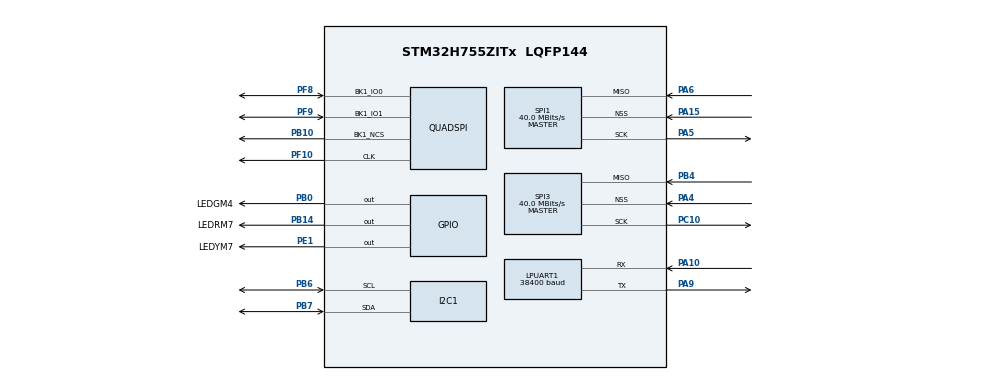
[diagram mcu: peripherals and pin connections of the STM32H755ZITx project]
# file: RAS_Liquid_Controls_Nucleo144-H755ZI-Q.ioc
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CORTEX_M7.default_mode_Activation=1
CortexM4.IPs=CORTEX_M4\:I,FATFS_M4\:I,FREERTOS_M4\:I,IWDG2\:I,OPENAMP_M4\:I,PDM2PCM_M4\:I,PWR,RCC,RESMGR_UTILITY,SYS_M4\:I,USB_DEVICE_M4\:I,USB_HOST_M4\:I,VREFBUF,WWDG2\:I,GPIO,DMA,BDMA,MDMA,NVIC2\:I,TIM7\:I,QUADSPI\:I
CortexM4.Pins=PB0
CortexM7.IPs=CORTEX_M7\:I,FATFS_M7\:I,FREERTOS_M7\:I,IWDG1\:I,OPENAMP_M7\:I,PDM2PCM_M7\:I,PWR\:I,RCC\:I,RESMGR_UTILITY\:I,SYS\:I,USB_DEVICE_M7\:I,USB_HOST_M7\:I,VREFBUF\:I,WWDG1\:I,GPIO\:I,DMA\:I,BDMA\:I,MDMA\:I,NVIC1\:I,TIM6\:I,SPI1\:I,SPI3\:I,I2C1\:I,LPUART1\:I
CortexM7.Pins=PB14,PE1
FREERTOS_M4.Tasks01=defaultTask,24,128,StartDefaultTask,Default,NULL,Dynamic,NULL,NULL
FREERTOS_M4.configUSE_NEWLIB_REENTRANT=1
FREERTOS_M7.Tasks01=defaultTask,24,128,StartDefaultTask,Default,NULL,Dynamic,NULL,NULL
FREERTOS_M7.configUSE_NEWLIB_REENTRANT=1
I2C1.Timing=0x00707CBB
LPUART1.BaudRate=38400
Mcu.Family=STM32H7
Mcu.Name=STM32H755ZITx
Mcu.Package=LQFP144
NVIC1.PriorityGroup=NVIC_PRIORITYGROUP_4
NVIC1.TIM6_DAC_IRQn=true\:15\:0\:false\:false\:true\:false\:false\:true\:true
NVIC1.TimeBase=TIM6_DAC_IRQn
NVIC1.TimeBaseIP=TIM6
NVIC2.PriorityGroup=NVIC_PRIORITYGROUP_4
NVIC2.TIM7_IRQn=true\:15\:0\:false\:false\:true\:false\:false\:true\:true
NVIC2.TimeBase=TIM7_IRQn
NVIC2.TimeBaseIP=TIM7
PA10.Mode=Asynchronous
PA10.PinAttribute=CortexM7
PA10.Signal=LPUART1_RX
PA15\ (JTDI).Mode=NSS_Signal_Hard_Input
PA15\ (JTDI).PinAttribute=CortexM7
PA15\ (JTDI).Signal=SPI1_NSS
PA4.Mode=NSS_Signal_Hard_Input
PA4.PinAttribute=CortexM7
PA4.Signal=SPI3_NSS
PA5.Mode=RX_Only_Simplex_Unidirect_Master
PA5.PinAttribute=CortexM7
PA5.Signal=SPI1_SCK
PA6.Mode=RX_Only_Simplex_Unidirect_Master
PA6.PinAttribute=CortexM7
PA6.Signal=SPI1_MISO
PA9.Mode=Asynchronous
PA9.PinAttribute=CortexM7
PA9.Signal=LPUART1_TX
PB0.GPIO_Label=LEDGM4
PB0.PinAttribute=CortexM4
PB0.Signal=GPIO_Output
PB10.Mode=Single Bank 1 2IOs
PB10.PinAttribute=CortexM4
PB10.Signal=QUADSPI_BK1_NCS
PB14.GPIO_Label=LEDRM7
PB14.PinAttribute=CortexM7
PB14.Signal=GPIO_Output
PB4\ (NJTRST).Mode=RX_Only_Simplex_Unidirect_Master
PB4\ (NJTRST).PinAttribute=CortexM7
PB4\ (NJTRST).Signal=SPI3_MISO
PB6.Mode=I2C
PB6.PinAttribute=CortexM7
PB6.Signal=I2C1_SCL
PB7.Mode=I2C
PB7.PinAttribute=CortexM7
PB7.Signal=I2C1_SDA
PC10.Mode=RX_Only_Simplex_Unidirect_Master
PC10.PinAttribute=CortexM7
PC10.Signal=SPI3_SCK
PE1.GPIO_Label=LEDYM7
PE1.PinAttribute=CortexM7
PE1.Signal=GPIO_Output
PF10.Mode=Single Bank 1 2IOs
PF10.PinAttribute=CortexM4
PF10.Signal=QUADSPI_CLK
PF8.Mode=Single Bank 1 2IOs
PF8.PinAttribute=CortexM4
PF8.Signal=QUADSPI_BK1_IO0
PF9.Mode=Single Bank 1 2IOs
PF9.PinAttribute=CortexM4
PF9.Signal=QUADSPI_BK1_IO1
ProjectManager.HeapSize=M4-0x200,M7-0x200
ProjectManager.StackSize=M4-0x400,M7-0x400
ProjectManager.TargetToolchain=STM32CubeIDE
RCC.ADCFreq_Value=129000000
RCC.APB1Freq_Value=32000000
RCC.APB2Freq_Value=64000000
RCC.APB3Freq_Value=32000000
RCC.APB4Freq_Value=64000000
RCC.CortexFreq_Value=64000000
RCC.D1PPRE=RCC_APB3_DIV2
RCC.D2PPRE1=RCC_APB1_DIV2
RCC.DIVM1=4
RCC.DIVN1=10
RCC.HCLKFreq_Value=64000000
RCC.PLLFRACN=0
RCC.SYSCLKFreq_VALUE=64000000
RCC.USBFreq_Value=80000000
SPI1.CalculateBaudRate=40.0 MBits/s
SPI1.Direction=SPI_DIRECTION_2LINES_RXONLY
SPI1.Mode=SPI_MODE_MASTER
SPI1.VirtualNSS=VM_NSSHARD
SPI1.VirtualType=VM_MASTER
SPI3.CalculateBaudRate=40.0 MBits/s
SPI3.Direction=SPI_DIRECTION_2LINES_RXONLY
SPI3.Mode=SPI_MODE_MASTER
SPI3.VirtualNSS=VM_NSSHARD
SPI3.VirtualType=VM_MASTER
SYS.userName=SYS_M7
VP_FREERTOS_M4_VS_CMSIS_V2.Mode=CMSIS_V2
VP_FREERTOS_M7_VS_CMSIS_V2.Mode=CMSIS_V2
VP_SYS_M4_VS_tim7.Mode=TIM7
VP_SYS_VS_tim6.Mode=TIM6
board=custom

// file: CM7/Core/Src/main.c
/* USER CODE BEGIN Header */
/**
  ******************************************************************************
  * @file           : main.c
  * @brief          : Main program body
  ******************************************************************************
  * @attention
  *
  * Copyright (c) 2026 STMicroelectronics.
  * All rights reserved.
  *
  * This software is licensed under terms that can be found in the LICENSE file
  * in the root directory of this software component.
  * If no LICENSE file comes with this software, it is provided AS-IS.
  *
  ******************************************************************************
  */
/* USER CODE END Header */
#include "main.h"
#include "FreeRTOS.h"
#include "cmsis_os2.h"

/* USER CODE BEGIN PD */

/* DUAL_CORE_BOOT_SYNC_SEQUENCE: Define for dual core boot synchronization    */
/*                             demonstration code based on hardware semaphore */
/* This define is present in both CM7/CM4 projects                            */
/* To comment when developping/debugging on a single core                     */
#define DUAL_CORE_BOOT_SYNC_SEQUENCE

#if defined(DUAL_CORE_BOOT_SYNC_SEQUENCE)
#ifndef HSEM_ID_0
#define HSEM_ID_0 (0U) /* HW semaphore 0*/
#endif
#endif /* DUAL_CORE_BOOT_SYNC_SEQUENCE */

/* USER CODE END PD */

I2C_HandleTypeDef hi2c1;

UART_HandleTypeDef hlpuart1;

SPI_HandleTypeDef hspi1;
SPI_HandleTypeDef hspi3;

/* Definitions for defaultTask */
osThreadId_t defaultTaskHandle;
const osThreadAttr_t defaultTask_attributes = {
  .name = "defaultTask",
  .stack_size = 128 * 4,
  .priority = (osPriority_t) osPriorityNormal,
};

void SystemClock_Config(void);
static void MPU_Config(void);
static void MX_GPIO_Init(void);
static void MX_I2C1_Init(void);
static void MX_LPUART1_UART_Init(void);
static void MX_SPI1_Init(void);
static void MX_SPI3_Init(void);
void StartDefaultTask(void *argument);

int main(void)
{

/* USER CODE BEGIN Boot_Mode_Sequence_0 */
#if defined(DUAL_CORE_BOOT_SYNC_SEQUENCE)
  int32_t timeout;
#endif /* DUAL_CORE_BOOT_SYNC_SEQUENCE */
/* USER CODE END Boot_Mode_Sequence_0 */

  /* MPU Configuration--------------------------------------------------------*/
  MPU_Config();

/* USER CODE BEGIN Boot_Mode_Sequence_1 */
#if defined(DUAL_CORE_BOOT_SYNC_SEQUENCE)
  /* Wait until CPU2 boots and enters in stop mode or timeout*/
  timeout = 0xFFFF;
  while((__HAL_RCC_GET_FLAG(RCC_FLAG_D2CKRDY) != RESET) && (timeout-- > 0));
  if ( timeout < 0 )
  {
	  Error_Handler();
  }
#endif /* DUAL_CORE_BOOT_SYNC_SEQUENCE */
/* USER CODE END Boot_Mode_Sequence_1 */
  /* MCU Configuration--------------------------------------------------------*/

  /* Reset of all peripherals, Initializes the Flash interface and the Systick. */
  HAL_Init();

  /* Configure the system clock */
  SystemClock_Config();
/* USER CODE BEGIN Boot_Mode_Sequence_2 */

#if defined(DUAL_CORE_BOOT_SYNC_SEQUENCE)
/* When system initialization is finished, Cortex-M7 will release Cortex-M4 by means of
HSEM notification */
/*HW semaphore Clock enable*/
__HAL_RCC_HSEM_CLK_ENABLE();
/*Take HSEM */
HAL_HSEM_FastTake(HSEM_ID_0);
/*Release HSEM in order to notify the CPU2(CM4)*/
HAL_HSEM_Release(HSEM_ID_0,0);
/* wait until CPU2 wakes up from stop mode */
timeout = 0xFFFF;
while((__HAL_RCC_GET_FLAG(RCC_FLAG_D2CKRDY) == RESET) && (timeout-- > 0));
if ( timeout < 0 )
{
	Error_Handler();
}
#endif /* DUAL_CORE_BOOT_SYNC_SEQUENCE */
/* USER CODE END Boot_Mode_Sequence_2 */

  /* Initialize all configured peripherals */
  MX_GPIO_Init();
  MX_I2C1_Init();
  MX_LPUART1_UART_Init();
  MX_SPI1_Init();
  MX_SPI3_Init();
  /* USER CODE BEGIN 2 */
  //LED DEBUG
  //HAL_GPIO_WritePin(LEDGM7_GPIO_Port, LEDGM7_Pin, GPIO_PIN_SET);   /* green solid */
  /* USER CODE END 2 */

  /* Init scheduler */
  osKernelInitialize();

  /* Create the thread(s) */
  /* creation of defaultTask */
  defaultTaskHandle = osThreadNew(StartDefaultTask, NULL, &defaultTask_attributes);

  /* Start scheduler */
  osKernelStart();

  /* We should never get here as control is now taken by the scheduler */

  /* Infinite loop */
  while (1)
  {

  }
}

void SystemClock_Config(void)
{
  RCC_OscInitTypeDef RCC_OscInitStruct = {0};
  RCC_ClkInitTypeDef RCC_ClkInitStruct = {0};

  /** Supply configuration update enable
  */
  HAL_PWREx_ConfigSupply(PWR_DIRECT_SMPS_SUPPLY);

  /** Configure the main internal regulator output voltage
  */
  __HAL_PWR_VOLTAGESCALING_CONFIG(PWR_REGULATOR_VOLTAGE_SCALE3);

  while(!__HAL_PWR_GET_FLAG(PWR_FLAG_VOSRDY)) {}

  /** Initializes the RCC Oscillators according to the specified parameters
  * in the RCC_OscInitTypeDef structure.
  */
  RCC_OscInitStruct.OscillatorType = RCC_OSCILLATORTYPE_HSI;
  RCC_OscInitStruct.HSIState = RCC_HSI_DIV1;
  RCC_OscInitStruct.HSICalibrationValue = RCC_HSICALIBRATION_DEFAULT;
  RCC_OscInitStruct.PLL.PLLState = RCC_PLL_ON;
  RCC_OscInitStruct.PLL.PLLSource = RCC_PLLSOURCE_HSI;
  RCC_OscInitStruct.PLL.PLLM = 4;
  RCC_OscInitStruct.PLL.PLLN = 10;
  RCC_OscInitStruct.PLL.PLLP = 2;
  RCC_OscInitStruct.PLL.PLLQ = 2;
  RCC_OscInitStruct.PLL.PLLR = 2;
  RCC_OscInitStruct.PLL.PLLRGE = RCC_PLL1VCIRANGE_3;
  RCC_OscInitStruct.PLL.PLLVCOSEL = RCC_PLL1VCOMEDIUM;
  RCC_OscInitStruct.PLL.PLLFRACN = 0;
  if (HAL_RCC_OscConfig(&RCC_OscInitStruct) != HAL_OK)
  {
    Error_Handler();
  }

  /** Initializes the CPU, AHB and APB buses clocks
  */
  RCC_ClkInitStruct.ClockType = RCC_CLOCKTYPE_HCLK|RCC_CLOCKTYPE_SYSCLK
                              |RCC_CLOCKTYPE_PCLK1|RCC_CLOCKTYPE_PCLK2
                              |RCC_CLOCKTYPE_D3PCLK1|RCC_CLOCKTYPE_D1PCLK1;
  RCC_ClkInitStruct.SYSCLKSource = RCC_SYSCLKSOURCE_HSI;
  RCC_ClkInitStruct.SYSCLKDivider = RCC_SYSCLK_DIV1;
  RCC_ClkInitStruct.AHBCLKDivider = RCC_HCLK_DIV1;
  RCC_ClkInitStruct.APB3CLKDivider = RCC_APB3_DIV2;
  RCC_ClkInitStruct.APB1CLKDivider = RCC_APB1_DIV2;
  RCC_ClkInitStruct.APB2CLKDivider = RCC_APB2_DIV1;
  RCC_ClkInitStruct.APB4CLKDivider = RCC_APB4_DIV1;

  if (HAL_RCC_ClockConfig(&RCC_ClkInitStruct, FLASH_LATENCY_1) != HAL_OK)
  {
    Error_Handler();
  }
}

static void MX_I2C1_Init(void)
{

  hi2c1.Instance = I2C1;
  hi2c1.Init.Timing = 0x00707CBB;
  hi2c1.Init.OwnAddress1 = 0;
  hi2c1.Init.AddressingMode = I2C_ADDRESSINGMODE_7BIT;
  hi2c1.Init.DualAddressMode = I2C_DUALADDRESS_DISABLE;
  hi2c1.Init.OwnAddress2 = 0;
  hi2c1.Init.OwnAddress2Masks = I2C_OA2_NOMASK;
  hi2c1.Init.GeneralCallMode = I2C_GENERALCALL_DISABLE;
  hi2c1.Init.NoStretchMode = I2C_NOSTRETCH_DISABLE;
  if (HAL_I2C_Init(&hi2c1) != HAL_OK)
  {
    Error_Handler();
  }

  /** Configure Analogue filter
  */
  if (HAL_I2CEx_ConfigAnalogFilter(&hi2c1, I2C_ANALOGFILTER_ENABLE) != HAL_OK)
  {
    Error_Handler();
  }

  /** Configure Digital filter
  */
  if (HAL_I2CEx_ConfigDigitalFilter(&hi2c1, 0) != HAL_OK)
  {
    Error_Handler();
  }

}

static void MX_LPUART1_UART_Init(void)
{

  hlpuart1.Instance = LPUART1;
  hlpuart1.Init.BaudRate = 38400;
  hlpuart1.Init.WordLength = UART_WORDLENGTH_8B;
  hlpuart1.Init.StopBits = UART_STOPBITS_1;
  hlpuart1.Init.Parity = UART_PARITY_NONE;
  hlpuart1.Init.Mode = UART_MODE_TX_RX;
  hlpuart1.Init.HwFlowCtl = UART_HWCONTROL_NONE;
  hlpuart1.Init.OneBitSampling = UART_ONE_BIT_SAMPLE_DISABLE;
  hlpuart1.Init.ClockPrescaler = UART_PRESCALER_DIV1;
  hlpuart1.AdvancedInit.AdvFeatureInit = UART_ADVFEATURE_NO_INIT;
  hlpuart1.FifoMode = UART_FIFOMODE_DISABLE;
  if (HAL_UART_Init(&hlpuart1) != HAL_OK)
  {
    Error_Handler();
  }
  if (HAL_UARTEx_SetTxFifoThreshold(&hlpuart1, UART_TXFIFO_THRESHOLD_1_8) != HAL_OK)
  {
    Error_Handler();
  }
  if (HAL_UARTEx_SetRxFifoThreshold(&hlpuart1, UART_RXFIFO_THRESHOLD_1_8) != HAL_OK)
  {
    Error_Handler();
  }
  if (HAL_UARTEx_DisableFifoMode(&hlpuart1) != HAL_OK)
  {
    Error_Handler();
  }

}

static void MX_SPI1_Init(void)
{

  /* SPI1 parameter configuration*/
  hspi1.Instance = SPI1;
  hspi1.Init.Mode = SPI_MODE_MASTER;
  hspi1.Init.Direction = SPI_DIRECTION_2LINES_RXONLY;
  hspi1.Init.DataSize = SPI_DATASIZE_4BIT;
  hspi1.Init.CLKPolarity = SPI_POLARITY_LOW;
  hspi1.Init.CLKPhase = SPI_PHASE_1EDGE;
  hspi1.Init.NSS = SPI_NSS_HARD_INPUT;
  hspi1.Init.BaudRatePrescaler = SPI_BAUDRATEPRESCALER_2;
  hspi1.Init.FirstBit = SPI_FIRSTBIT_MSB;
  hspi1.Init.TIMode = SPI_TIMODE_DISABLE;
  hspi1.Init.CRCCalculation = SPI_CRCCALCULATION_DISABLE;
  hspi1.Init.CRCPolynomial = 0x0;
  hspi1.Init.NSSPMode = SPI_NSS_PULSE_ENABLE;
  hspi1.Init.NSSPolarity = SPI_NSS_POLARITY_LOW;
  hspi1.Init.FifoThreshold = SPI_FIFO_THRESHOLD_01DATA;
  hspi1.Init.TxCRCInitializationPattern = SPI_CRC_INITIALIZATION_ALL_ZERO_PATTERN;
  hspi1.Init.RxCRCInitializationPattern = SPI_CRC_INITIALIZATION_ALL_ZERO_PATTERN;
  hspi1.Init.MasterSSIdleness = SPI_MASTER_SS_IDLENESS_00CYCLE;
  hspi1.Init.MasterInterDataIdleness = SPI_MASTER_INTERDATA_IDLENESS_00CYCLE;
  hspi1.Init.MasterReceiverAutoSusp = SPI_MASTER_RX_AUTOSUSP_DISABLE;
  hspi1.Init.MasterKeepIOState = SPI_MASTER_KEEP_IO_STATE_DISABLE;
  hspi1.Init.IOSwap = SPI_IO_SWAP_DISABLE;
  if (HAL_SPI_Init(&hspi1) != HAL_OK)
  {
    Error_Handler();
  }

}

static void MX_SPI3_Init(void)
{

  /* SPI3 parameter configuration*/
  hspi3.Instance = SPI3;
  hspi3.Init.Mode = SPI_MODE_MASTER;
  hspi3.Init.Direction = SPI_DIRECTION_2LINES_RXONLY;
  hspi3.Init.DataSize = SPI_DATASIZE_4BIT;
  hspi3.Init.CLKPolarity = SPI_POLARITY_LOW;
  hspi3.Init.CLKPhase = SPI_PHASE_1EDGE;
  hspi3.Init.NSS = SPI_NSS_HARD_INPUT;
  hspi3.Init.BaudRatePrescaler = SPI_BAUDRATEPRESCALER_2;
  hspi3.Init.FirstBit = SPI_FIRSTBIT_MSB;
  hspi3.Init.TIMode = SPI_TIMODE_DISABLE;
  hspi3.Init.CRCCalculation = SPI_CRCCALCULATION_DISABLE;
  hspi3.Init.CRCPolynomial = 0x0;
  hspi3.Init.NSSPMode = SPI_NSS_PULSE_ENABLE;
  hspi3.Init.NSSPolarity = SPI_NSS_POLARITY_LOW;
  hspi3.Init.FifoThreshold = SPI_FIFO_THRESHOLD_01DATA;
  hspi3.Init.TxCRCInitializationPattern = SPI_CRC_INITIALIZATION_ALL_ZERO_PATTERN;
  hspi3.Init.RxCRCInitializationPattern = SPI_CRC_INITIALIZATION_ALL_ZERO_PATTERN;
  hspi3.Init.MasterSSIdleness = SPI_MASTER_SS_IDLENESS_00CYCLE;
  hspi3.Init.MasterInterDataIdleness = SPI_MASTER_INTERDATA_IDLENESS_00CYCLE;
  hspi3.Init.MasterReceiverAutoSusp = SPI_MASTER_RX_AUTOSUSP_DISABLE;
  hspi3.Init.MasterKeepIOState = SPI_MASTER_KEEP_IO_STATE_DISABLE;
  hspi3.Init.IOSwap = SPI_IO_SWAP_DISABLE;
  if (HAL_SPI_Init(&hspi3) != HAL_OK)
  {
    Error_Handler();
  }

}

static void MX_GPIO_Init(void)
{
  GPIO_InitTypeDef GPIO_InitStruct = {0};

  /* GPIO Ports Clock Enable */
  __HAL_RCC_GPIOA_CLK_ENABLE();
  __HAL_RCC_GPIOB_CLK_ENABLE();
  __HAL_RCC_GPIOC_CLK_ENABLE();
  __HAL_RCC_GPIOE_CLK_ENABLE();

  /*Configure GPIO pin Output Level */
  HAL_GPIO_WritePin(LEDRM7_GPIO_Port, LEDRM7_Pin, GPIO_PIN_RESET);

  /*Configure GPIO pin Output Level */
  HAL_GPIO_WritePin(LEDYM7_GPIO_Port, LEDYM7_Pin, GPIO_PIN_RESET);

  /*Configure GPIO pin : LEDRM7_Pin */
  GPIO_InitStruct.Pin = LEDRM7_Pin;
  GPIO_InitStruct.Mode = GPIO_MODE_OUTPUT_PP;
  GPIO_InitStruct.Pull = GPIO_NOPULL;
  GPIO_InitStruct.Speed = GPIO_SPEED_FREQ_LOW;
  HAL_GPIO_Init(LEDRM7_GPIO_Port, &GPIO_InitStruct);

  /*Configure GPIO pin : LEDYM7_Pin */
  GPIO_InitStruct.Pin = LEDYM7_Pin;
  GPIO_InitStruct.Mode = GPIO_MODE_OUTPUT_PP;
  GPIO_InitStruct.Pull = GPIO_NOPULL;
  GPIO_InitStruct.Speed = GPIO_SPEED_FREQ_LOW;
  HAL_GPIO_Init(LEDYM7_GPIO_Port, &GPIO_InitStruct);

}

void StartDefaultTask(void *argument)
{
  /* USER CODE BEGIN 5 */
  /* Infinite loop */
  for(;;)
  {
	  HAL_GPIO_TogglePin(LEDYM7_GPIO_Port, LEDYM7_Pin);
	  HAL_GPIO_TogglePin(LEDRM7_GPIO_Port, LEDRM7_Pin);
	  HAL_Delay(100);
	  //	  HAL_GPIO_WritePin(LEDRM7_GPIO_Port, LEDRM7_Pin, GPIO_PIN_SET);
  }
  /* USER CODE END 5 */
}

 /* MPU Configuration */

void MPU_Config(void)
{
  MPU_Region_InitTypeDef MPU_InitStruct = {0};

  /* Disables the MPU */
  HAL_MPU_Disable();

  /** Initializes and configures the Region and the memory to be protected
  */
  MPU_InitStruct.Enable = MPU_REGION_ENABLE;
  MPU_InitStruct.Number = MPU_REGION_NUMBER0;
  MPU_InitStruct.BaseAddress = 0x0;
  MPU_InitStruct.Size = MPU_REGION_SIZE_4GB;
  MPU_InitStruct.SubRegionDisable = 0x87;
  MPU_InitStruct.TypeExtField = MPU_TEX_LEVEL0;
  MPU_InitStruct.AccessPermission = MPU_REGION_NO_ACCESS;
  MPU_InitStruct.DisableExec = MPU_INSTRUCTION_ACCESS_DISABLE;
  MPU_InitStruct.IsShareable = MPU_ACCESS_SHAREABLE;
  MPU_InitStruct.IsCacheable = MPU_ACCESS_NOT_CACHEABLE;
  MPU_InitStruct.IsBufferable = MPU_ACCESS_NOT_BUFFERABLE;

  HAL_MPU_ConfigRegion(&MPU_InitStruct);
  /* Enables the MPU */
  HAL_MPU_Enable(MPU_PRIVILEGED_DEFAULT);

}

void HAL_TIM_PeriodElapsedCallback(TIM_HandleTypeDef *htim)
{
  if (htim->Instance == TIM6)
  {
    HAL_IncTick();
  }
}

void Error_Handler(void)
{
  __disable_irq();
  while (1)
  {
  }
}
